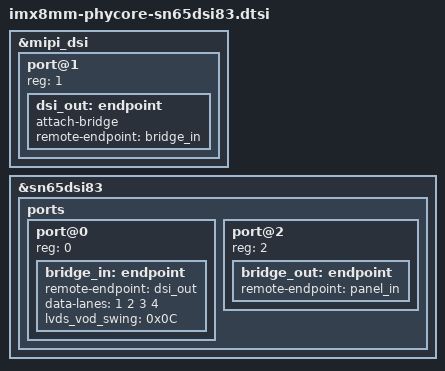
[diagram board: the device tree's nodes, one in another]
// SPDX-License-Identifier: GPL-2.0
/*
 * Copyright (C) 2019-2021 PHYTEC Messtechnik GmbH
 * Author: Teresa Remmet <t.remmet@phytec.de>
 * Enables the TI sn65dsi83 mipi-dsi bridge
 */

&mipi_dsi {
	status = "okay";

	#address-cells = <1>;
	#size-cells = <0>;

	port@1 {
		reg = <1>;

		dsi_out: endpoint {
			attach-bridge;
			remote-endpoint = <&bridge_in>;
		};
	};
};

&sn65dsi83 {
	status = "okay";

	ports {
		#address-cells = <1>;
		#size-cells = <0>;

		port@0 {
			reg = <0>;

			bridge_in: endpoint {
				remote-endpoint = <&dsi_out>;
				data-lanes = <1 2 3 4>;
				lvds_vod_swing = <0x0C>;
			};
		};

		port@2 {
			reg = <2>;

			bridge_out: endpoint {
				remote-endpoint = <&panel_in>;
			};
		};
	};
};
